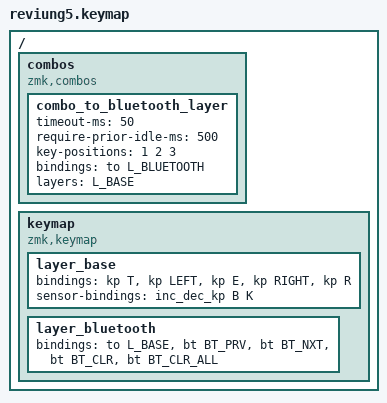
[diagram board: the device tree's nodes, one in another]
/*
 * Copyright (c) 2022 The ZMK Contributors
 *
 * SPDX-License-Identifier: MIT
 */

#include <behaviors.dtsi>
#include <dt-bindings/zmk/keys.h>
#include <dt-bindings/zmk/bt.h>

#define L_BASE 0
#define L_BLUETOOTH 1

/ {
		combos {
			compatible = "zmk,combos";
		
			combo_to_bluetooth_layer {
				timeout-ms = <50>;
				require-prior-idle-ms = <500>;
				key-positions = <1 2 3>;
				bindings = <&to L_BLUETOOTH>;
				layers = <L_BASE>;
			};
		};
		
        keymap {
            compatible = "zmk,keymap";

            layer_base {
              bindings = <
                // ╭───────┬─────────┬───────┬───────────┬───────╮
                     &kp T   &kp LEFT  &kp E   &kp RIGHT   &kp R
                // ╰───────┴─────────┴───────┴───────────┴───────╯
              >;
              sensor-bindings = <&inc_dec_kp B K>;
            };

            layer_bluetooth {
              bindings = <
                // ╭───────────┬─────────────┬─────────────┬─────────────┬───────────────╮
                     &to L_BASE  &bt BT_PRV    &bt BT_NXT    &bt BT_CLR    &bt BT_CLR_ALL
                // ╰───────────┴─────────────┴─────────────┴─────────────┴───────────────╯
              >;
            };
        };
};
